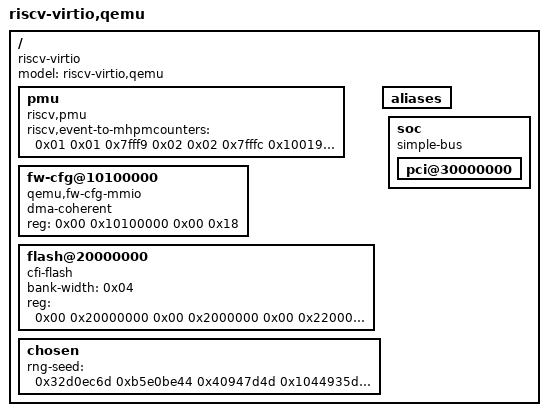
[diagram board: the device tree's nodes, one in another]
/dts-v1/;

/ {
	#address-cells = <0x02>;
	#size-cells = <0x02>;
	compatible = "riscv-virtio";
	model = "riscv-virtio,qemu";

	pmu {
		riscv,event-to-mhpmcounters = <0x01 0x01 0x7fff9 0x02 0x02 0x7fffc 0x10019 0x10019 0x7fff8 0x1001b 0x1001b 0x7fff8 0x10021 0x10021 0x7fff8>;
		compatible = "riscv,pmu";
	};

	fw-cfg@10100000 {
		dma-coherent;
		reg = <0x00 0x10100000 0x00 0x18>;
		compatible = "qemu,fw-cfg-mmio";
	};

	flash@20000000 {
		bank-width = <0x04>;
		reg = <0x00 0x20000000 0x00 0x2000000 0x00 0x22000000 0x00 0x2000000>;
		compatible = "cfi-flash";
	};

	aliases {
	};

	chosen {
		rng-seed = <0x32d0ec6d 0xb5e0be44 0x40947d4d 0x1044935d 0x83d28944 0x6fdcef92 0x22680f86 0x22be6636>;
	};

	soc {
		#address-cells = <0x02>;
		#size-cells = <0x02>;
		compatible = "simple-bus";
		ranges;

		pci@30000000 {
		};
	};
};
